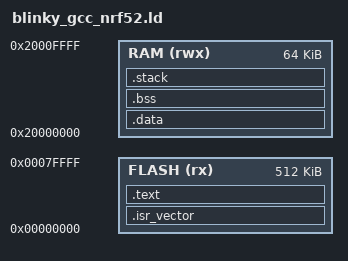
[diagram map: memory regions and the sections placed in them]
ENTRY(Reset_Handler)

MEMORY
{
  FLASH (rx) : ORIGIN = 0x00000000, LENGTH = 512K
  RAM   (rwx): ORIGIN = 0x20000000, LENGTH = 64K
}

SECTIONS
{
  .isr_vector :
  {
    . = ALIGN(4);
    KEEP(*(.isr_vector))
  } > FLASH

  .text :
  {
    . = ALIGN(4);
    *(.text*)
    *(.init*)
    *(.fini*)
    *(.rodata*)
    *(.rodata*)
    . = ALIGN(4);
    __etext = .;
  } > FLASH

  .data : AT(__etext)
  {
    . = ALIGN(4);
    __data_start__ = .;
    *(.data*)
    . = ALIGN(4);
    __data_end__ = .;
  } > RAM

  .bss :
  {
    . = ALIGN(4);
    __bss_start__ = .;
    *(.bss*)
    *(COMMON)
    . = ALIGN(4);
    __bss_end__ = .;
  } > RAM

  .stack (NOLOAD) :
  {
    . = ALIGN(8);
    __StackLimit = .;
    . = . + 0x1000;
    __StackTop = .;
  } > RAM
}
